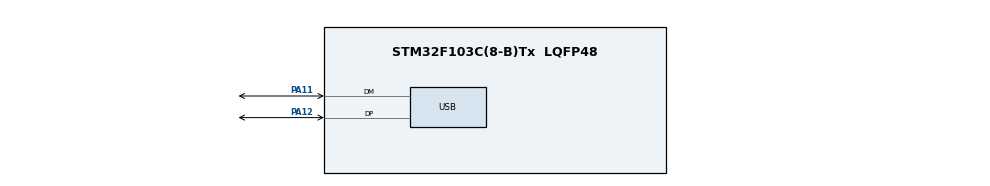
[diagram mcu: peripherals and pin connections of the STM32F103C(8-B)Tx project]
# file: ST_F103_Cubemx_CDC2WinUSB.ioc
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Mcu.Family=STM32F1
Mcu.Name=STM32F103C(8-B)Tx
Mcu.Package=LQFP48
NVIC.PriorityGroup=NVIC_PRIORITYGROUP_4
NVIC.USB_LP_CAN1_RX0_IRQn=true\:0\:0\:false\:false\:true\:true\:true\:true
PA11.Mode=Device
PA11.Signal=USB_DM
PA12.Mode=Device
PA12.Signal=USB_DP
PA13.Mode=Serial_Wire
PA13.Signal=SYS_JTMS-SWDIO
PA14.Mode=Serial_Wire
PA14.Signal=SYS_JTCK-SWCLK
PD0-OSC_IN.Mode=HSE-External-Oscillator
PD0-OSC_IN.Signal=RCC_OSC_IN
PD1-OSC_OUT.Mode=HSE-External-Oscillator
PD1-OSC_OUT.Signal=RCC_OSC_OUT
ProjectManager.HeapSize=0x200
ProjectManager.StackSize=0x400
ProjectManager.TargetToolchain=STM32CubeIDE
RCC.AHBFreq_Value=72000000
RCC.APB1CLKDivider=RCC_HCLK_DIV2
RCC.APB1Freq_Value=36000000
RCC.APB1TimFreq_Value=72000000
RCC.APB2Freq_Value=72000000
RCC.APB2TimFreq_Value=72000000
RCC.HCLKFreq_Value=72000000
RCC.PLLMUL=RCC_PLL_MUL9
RCC.SYSCLKFreq_VALUE=72000000
RCC.SYSCLKSource=RCC_SYSCLKSOURCE_PLLCLK
RCC.USBFreq_Value=48000000
RCC.USBPrescaler=RCC_USBCLKSOURCE_PLL_DIV1_5
USB_DEVICE.CLASS_NAME_FS=CDC
USB_DEVICE.VirtualMode=Cdc
USB_DEVICE.VirtualModeFS=Cdc_FS
VP_USB_DEVICE_VS_USB_DEVICE_CDC_FS.Mode=CDC_FS
board=custom

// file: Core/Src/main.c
/* USER CODE BEGIN Header */
/**
  ******************************************************************************
  * @file           : main.c
  * @brief          : Main program body
  ******************************************************************************
  * @attention
  *
  * Copyright (c) 2022 STMicroelectronics.
  * All rights reserved.
  *
  * This software is licensed under terms that can be found in the LICENSE file
  * in the root directory of this software component.
  * If no LICENSE file comes with this software, it is provided AS-IS.
  *
  ******************************************************************************
  */
/* USER CODE END Header */
#include "main.h"
#include "usb_device.h"
#include "gpio.h"

/* USER CODE BEGIN Includes */
#include "usbd_cdc_if.h"
/* USER CODE END Includes */

void SystemClock_Config(void);

int main(void)
{

  /* MCU Configuration--------------------------------------------------------*/

  /* Reset of all peripherals, Initializes the Flash interface and the Systick. */
  HAL_Init();

  /* Configure the system clock */
  SystemClock_Config();

  /* Initialize all configured peripherals */
  MX_GPIO_Init();
  MX_USB_DEVICE_Init();

  /* Infinite loop */
  /* USER CODE BEGIN WHILE */
  while (1)
  {
      char str[] = "hello stm32cubemx_winusb_demo\r\n";
      CDC_Transmit_FS(str,strlen(str));
      HAL_Delay(500);
    /* USER CODE END WHILE */

  }
}

void SystemClock_Config(void)
{
  LL_FLASH_SetLatency(LL_FLASH_LATENCY_2);
  while(LL_FLASH_GetLatency()!= LL_FLASH_LATENCY_2)
  {
  }
  LL_RCC_HSE_Enable();

   /* Wait till HSE is ready */
  while(LL_RCC_HSE_IsReady() != 1)
  {

  }
  LL_RCC_PLL_ConfigDomain_SYS(LL_RCC_PLLSOURCE_HSE_DIV_1, LL_RCC_PLL_MUL_9);
  LL_RCC_PLL_Enable();

   /* Wait till PLL is ready */
  while(LL_RCC_PLL_IsReady() != 1)
  {

  }
  LL_RCC_SetAHBPrescaler(LL_RCC_SYSCLK_DIV_1);
  LL_RCC_SetAPB1Prescaler(LL_RCC_APB1_DIV_2);
  LL_RCC_SetAPB2Prescaler(LL_RCC_APB2_DIV_1);
  LL_RCC_SetSysClkSource(LL_RCC_SYS_CLKSOURCE_PLL);

   /* Wait till System clock is ready */
  while(LL_RCC_GetSysClkSource() != LL_RCC_SYS_CLKSOURCE_STATUS_PLL)
  {

  }
  LL_SetSystemCoreClock(72000000);

   /* Update the time base */
  if (HAL_InitTick (TICK_INT_PRIORITY) != HAL_OK)
  {
    Error_Handler();
  }
  LL_RCC_SetUSBClockSource(LL_RCC_USB_CLKSOURCE_PLL_DIV_1_5);
}

void Error_Handler(void)
{
  __disable_irq();
  while (1)
  {
  }
}
